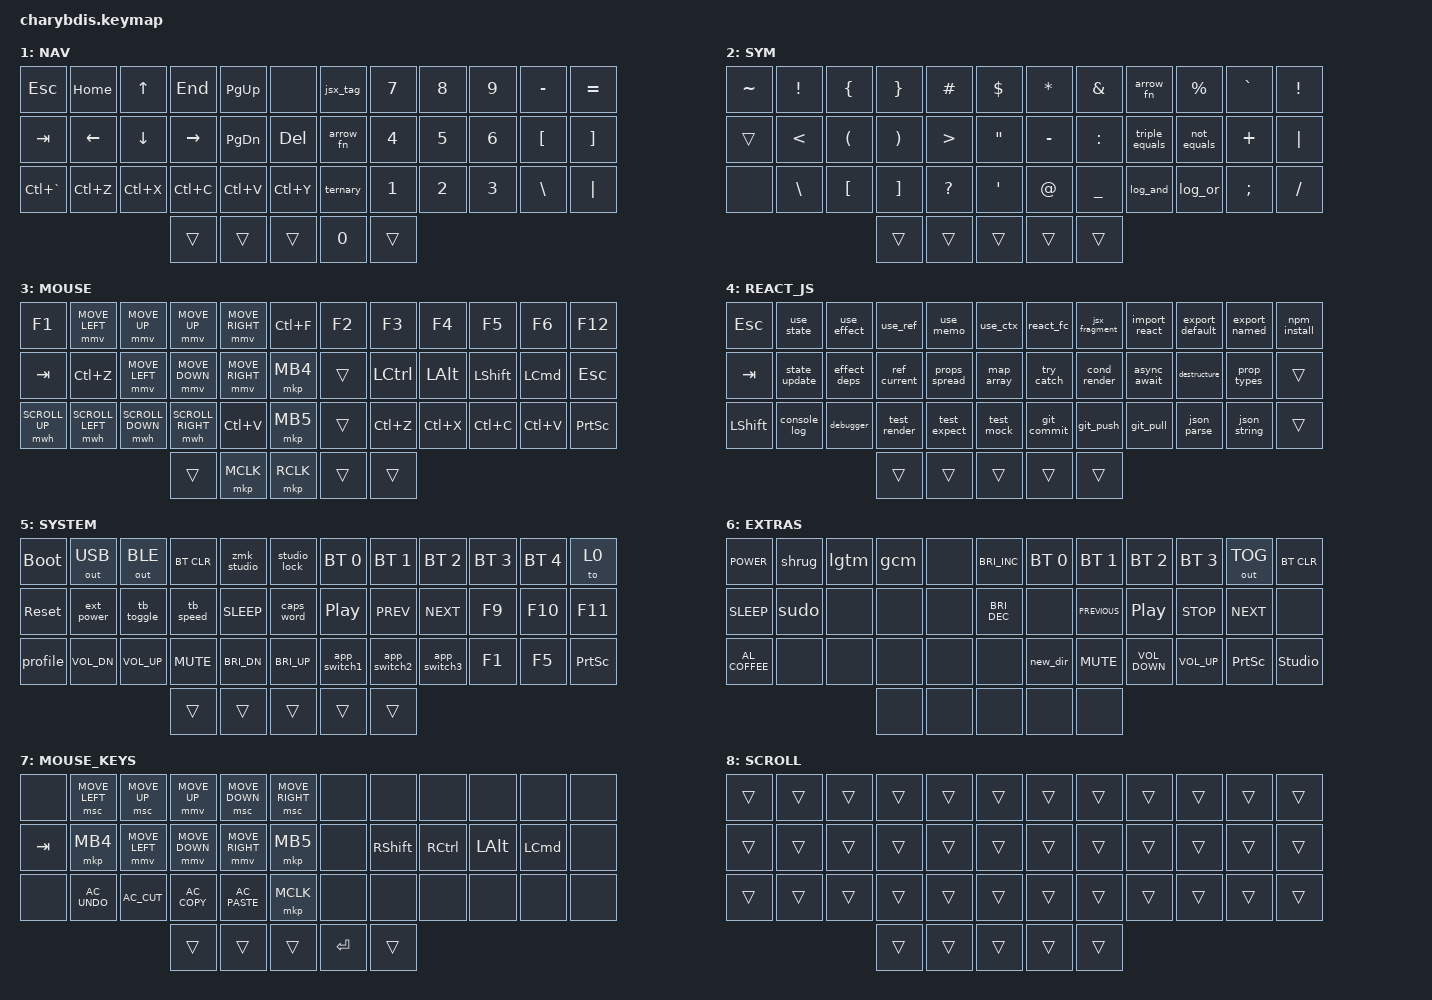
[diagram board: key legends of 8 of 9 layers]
#include <behaviors/mouse_keys.dtsi>
#include <behaviors.dtsi>
#include <dt-bindings/zmk/bt.h>
#include <dt-bindings/zmk/keys.h>
#include <dt-bindings/zmk/mouse.h>
#include <dt-bindings/zmk/outputs.h>

#define U_TAPPING_TERM 200

/ {
    chosen { zmk,matrix_transform = &default_transform; };
};

/ {
    combos {
        compatible = "zmk,combos";

        // Caps Word combo
        CapsWord {
            bindings = <&caps_word>;
            key-positions = <17 18>;
            layers = <0>;
        };

        // Mouse button combos
        MiddleClick {
            bindings = <&mkp MCLK>;
            key-positions = <28 37>;
        };

        RightClick {
            bindings = <&mkp RCLK>;
            key-positions = <16 37>;
        };

        // React/JS layer combo (A+O)
        ReactJSLayer {
            bindings = <&os_react 4>;
            key-positions = <12 22>; // A and O keys
            layers = <0>;
            timeout-ms = <75>; // Strict timing for intentional activation
        };

        // Inner thumb escape combo
        InnerThumbEsc {
            bindings = <&kp ESC>;
            key-positions = <38 39>; // Space and Return keys
            timeout-ms = <150>;
            layers = <0>;
        };

        // Mouse acceleration toggle combo
        MouseAccelToggle {
            bindings = <&mouse_accel_toggle>;
            key-positions = <27 32>; // C and comma keys (center of bottom row)
            timeout-ms = <100>;
            layers = <0 3>; // Available on base layer and mouse layer
        };
    };

    behaviors {
        trackball_listener {
            compatible = "zmk,input-behavior-listener";
            device = <&trackball>;
            layers = <0 1 2>;  // Active on your main layers
            evt-type = <INPUT_EV_REL>;
            x-input-code = <INPUT_REL_X>;
            y-input-code = <INPUT_REL_Y>;
            scale-multiplier = <4>;
            scale-divisor = <5>;
        };
    
        /* Scroll mode configuration */
        trackball_scroll_listener {
            compatible = "zmk,input-behavior-listener";
            device = <&trackball>;
            layers = <5>;  // Using layer 5 for scroll mode
            evt-type = <INPUT_EV_REL>;
            x-input-code = <INPUT_REL_MISC>;  // Horizontal scroll
            y-input-code = <INPUT_REL_WHEEL>; // Vertical scroll
            y-invert;  // Makes scrolling direction feel more natural
            bindings = <&ib_wheel_scaler 1 10>;  // Adjusted for smoother scrolling
        };
    
        /* Scroll wheel scaling behavior */
        ib_wheel_scaler: ib_wheel_scaler {
            compatible = "zmk,input-behavior-scaler";
            #binding-cells = <2>;
            evt-type = <INPUT_EV_REL>;
            input-code = <INPUT_REL_WHEEL>;
        };

        u_mt: u_mt {
            compatible = "zmk,behavior-hold-tap";
            label = "u_mt";
            #binding-cells = <2>;
            tapping_term_ms = <U_TAPPING_TERM>;
            flavor = "tap-preferred";
            bindings = <&kp>, <&kp>;
        };

        u_lt: u_lt {
            compatible = "zmk,behavior-hold-tap";
            label = "u_lt";
            #binding-cells = <2>;
            tapping_term_ms = <U_TAPPING_TERM>;
            flavor = "tap-preferred";
            bindings = <&mo>, <&kp>;
        };

        hm: homerow_mod {
            compatible = "zmk,behavior-hold-tap";
            #binding-cells = <2>;
            flavor = "tap-preferred";
            tapping-term-ms = <175>; // triggers the hold behavior when the tapping-term-ms has expired
            quick-tap-ms = <150>; // If you press a tapped hold-tap again within quick-tap-ms milliseconds of the first press, it will always trigger the tap behavior.
            require-prior-idle-ms = <185>; // like quick-tap-ms however it will apply for any non-modifier key pressed before it
            bindings = <&kp>, <&kp>;  // hold, tap
        };

        hm_right: homerow_mod_right {
            compatible = "zmk,behavior-hold-tap";
            #binding-cells = <2>;
            flavor = "tap-preferred";
            tapping-term-ms = <130>;
            // quick-tap-ms = <200>;
            // require-prior-idle-ms = <150>;
            bindings = <&kp>, <&kp>;
            hold-trigger-key-positions = <0 1 2 3 4 5 12 13 14 15 16 17 24 25 26 27 28 29 36 37 38>;
        };

        hm_left: homerow_mod_left {
            compatible = "zmk,behavior-hold-tap";
            #binding-cells = <2>;
            flavor = "tap-preferred";
            tapping-term-ms = <130>;
            // quick-tap-ms = <200>;
            // require-prior-idle-ms = <150>;
            bindings = <&kp>, <&kp>;
            hold-trigger-key-positions = <6 7 8 9 10 11 18 19 20 21 22 23 30 31 32 33 34 35 39 40>;
        };

        td_cursor: td_scroll_or_cursor {
            compatible = "zmk,behavior-tap-dance";
            #binding-cells = <0>;
            bindings = <&lt 9 ESC>, <&mo 8>; // hold, tap, double_tap
        };

        td_space: td_space {
            compatible = "zmk,behavior-tap-dance";
            #binding-cells = <0>;
            tapping-term-ms = <85>;
            bindings = <&kp SPACE>, <&kp SPACE>; // hold, tap, double_tap
        };

        td_bs: td_bs {
            compatible = "zmk,behavior-tap-dance";
            #binding-cells = <0>;
            tapping-term-ms = <85>;
            bindings = <&kp BACKSPACE>, <&kp BACKSPACE>; // hold, tap, double_tap
        };

        httl: ht_two_layers {
            compatible = "zmk,behavior-hold-tap";
            bindings = <&mo>, <&to>;
            #binding-cells = <2>;
            flavor = "balanced";
            tapping-term-ms = <125>;
        };

        td_layers: td_layer_swap {
            compatible = "zmk,behavior-tap-dance";
            #binding-cells = <0>;
            bindings = <&to 0>, <&to 5>, <&to 6>; // tap, double_tap, tripple_tap
        };

        td_clk_scrl: td_click_or_scroll {
            compatible = "zmk,behavior-tap-dance";
            #binding-cells = <0>;
            tapping-term-ms = <250>;
            bindings = <&mkp RCLK>, <&mo 8>;  // tap/hold, double_tap
        };

        Shift_Enter: Shift_Enter {
            compatible = "zmk,behavior-hold-tap";
            label = "SHIFT_ENTER";
            bindings = <&kp>, <&kp>;

            #binding-cells = <2>;
            hold-trigger-key-positions = <40>;
            tapping-term-ms = <100>;
        };

    macros {
        clip_hist: clip_hist { // CLIPBOARD_HISTORY
            compatible = "zmk,behavior-macro";
            #binding-cells = <0>;
            bindings
                = <&macro_press &kp LGUI>
                , <&macro_tap &kp V>
                , <&macro_release &kp LGUI>
                ;
        };

        studio_unlock_macro: studio_unlock {
            compatible = "zmk,behavior-macro";
            #binding-cells = <0>;
            bindings
                = <&macro_tap &kp LC(K) &kp U>
                ;
        };
        
        // JavaScript Operators
        arrow_fn: arrow_fn {
            compatible = "zmk,behavior-macro";
            #binding-cells = <0>;
            bindings = <&macro_tap &kp EQUAL &kp GREATER_THAN &kp SPACE>;
        };

        ternary: ternary {
            compatible = "zmk,behavior-macro";
            #binding-cells = <0>;
            bindings = <&macro_tap &kp QUESTION &kp SPACE &kp COLON &kp SPACE>;
        };

        triple_equals: triple_equals {
            compatible = "zmk,behavior-macro";
            #binding-cells = <0>;
            bindings = <&macro_tap &kp EQUAL &kp EQUAL &kp EQUAL>;
        };

        not_equals: not_equals {
            compatible = "zmk,behavior-macro";
            #binding-cells = <0>;
            bindings = <&macro_tap &kp EXCL &kp EQUAL &kp EQUAL>;
        };

        log_and: log_and {
            compatible = "zmk,behavior-macro";
            #binding-cells = <0>;
            bindings = <&macro_tap &kp AMPS &kp AMPS>;
        };

        log_or: log_or {
            compatible = "zmk,behavior-macro";
            #binding-cells = <0>;
            bindings = <&macro_tap &kp PIPE &kp PIPE>;
        };

        jsx_tag: jsx_tag {
            compatible = "zmk,behavior-macro";
            #binding-cells = <0>;
            bindings = <&macro_tap
                &kp LT
                &kp GREATER_THAN
                &kp LEFT_ARROW
                &kp LEFT_ARROW
                &kp SLASH
                &kp GREATER_THAN>;
        };

        // React Hooks
        use_state: use_state {
            compatible = "zmk,behavior-macro";
            #binding-cells = <0>;
            bindings = <&macro_tap
                &kp C &kp O &kp N &kp S &kp T &kp SPACE &kp LBKT
                &kp S &kp T &kp A &kp T &kp E &kp COMMA &kp SPACE
                &kp S &kp E &kp T &kp S &kp T &kp A &kp T &kp E
                &kp RBKT &kp SPACE &kp EQUAL &kp SPACE
                &kp U &kp S &kp E &kp S &kp T &kp A &kp T &kp E &kp LPAR &kp RPAR &kp SEMI>;
        };

        use_effect: use_effect {
            compatible = "zmk,behavior-macro";
            #binding-cells = <0>;
            bindings = <&macro_tap
                &kp U &kp S &kp E &kp E &kp F &kp F &kp E &kp C &kp T &kp LPAR
                &kp LPAR &kp RPAR &kp SPACE &kp EQUAL &kp GREATER_THAN &kp SPACE
                &kp LBRC &kp ENTER &kp ENTER &kp RBRC &kp COMMA &kp SPACE
                &kp LBKT &kp RBKT &kp RPAR &kp SEMI &kp UP &kp UP>;
        };

        use_ref: use_ref {
            compatible = "zmk,behavior-macro";
            #binding-cells = <0>;
            bindings = <&macro_tap
                &kp C &kp O &kp N &kp S &kp T &kp SPACE
                &kp R &kp E &kp F &kp SPACE &kp EQUAL &kp SPACE
                &kp U &kp S &kp E &kp R &kp E &kp F &kp LPAR &kp N &kp U &kp L &kp L &kp RPAR &kp SEMI>;
        };

        use_memo: use_memo {
            compatible = "zmk,behavior-macro";
            #binding-cells = <0>;
            bindings = <&macro_tap
                &kp C &kp O &kp N &kp S &kp T &kp SPACE
                &kp M &kp E &kp M &kp O &kp I &kp Z &kp E &kp D &kp SPACE &kp EQUAL &kp SPACE
                &kp U &kp S &kp E &kp M &kp E &kp M &kp O &kp LPAR &kp LPAR &kp RPAR &kp SPACE &kp EQUAL &kp GREATER_THAN &kp SPACE
                &kp LBRC &kp ENTER &kp ENTER &kp RBRC &kp COMMA &kp SPACE
                &kp LBKT &kp RBKT &kp RPAR &kp SEMI>;
        };

        use_ctx: use_ctx {
            compatible = "zmk,behavior-macro";
            #binding-cells = <0>;
            bindings = <&macro_tap
                &kp C &kp O &kp N &kp S &kp T &kp SPACE
                &kp V &kp A &kp L &kp U &kp E &kp SPACE &kp EQUAL &kp SPACE
                &kp U &kp S &kp E &kp C &kp O &kp N &kp T &kp E &kp X &kp T &kp LPAR
                &kp C &kp O &kp N &kp T &kp E &kp X &kp T &kp RPAR &kp SEMI>;
        };

        // React Components
        react_fc: react_fc {
            compatible = "zmk,behavior-macro";
            #binding-cells = <0>;
            bindings = <&macro_tap
                &kp C &kp O &kp N &kp S &kp T &kp SPACE
                &kp C &kp O &kp M &kp P &kp O &kp N &kp E &kp N &kp T &kp SPACE &kp EQUAL &kp SPACE
                &kp LPAR &kp LBRC &kp SPACE &kp P &kp R &kp O &kp P &kp S &kp SPACE &kp RBRC &kp RPAR &kp SPACE &kp EQUAL &kp GREATER_THAN &kp SPACE
                &kp LBRC &kp ENTER &kp ENTER &kp SPACE &kp SPACE &kp R &kp E &kp T &kp U &kp R &kp N &kp SPACE
                &kp LPAR &kp ENTER &kp SPACE &kp SPACE &kp SPACE &kp SPACE
                &kp LT &kp GT &kp LT &kp SLASH &kp GT &kp ENTER
                &kp SPACE &kp SPACE &kp RPAR &kp SEMI &kp ENTER
                &kp RBRC &kp SEMI>;
        };

        jsx_fragment: jsx_fragment {
            compatible = "zmk,behavior-macro";
            #binding-cells = <0>;
            bindings = <&macro_tap
                &kp LT &kp GT &kp ENTER
                &kp SPACE &kp SPACE
                &kp LT &kp SLASH &kp GT>;
        };

        // JS Utilities
        console_log: console_log {
            compatible = "zmk,behavior-macro";
            #binding-cells = <0>;
            bindings = <&macro_tap
                &kp C &kp O &kp N &kp S &kp O &kp L &kp E &kp DOT
                &kp L &kp O &kp G &kp LPAR &kp RPAR &kp SEMI>;
        };

        import_react: import_react {
            compatible = "zmk,behavior-macro";
            #binding-cells = <0>;
            bindings = <&macro_tap
                &kp I &kp M &kp P &kp O &kp R &kp T &kp SPACE
                &kp LBRC &kp SPACE &kp U &kp S &kp E &kp S &kp T &kp A &kp T &kp E &kp COMMA &kp SPACE
                &kp U &kp S &kp E &kp E &kp F &kp F &kp E &kp C &kp T &kp SPACE &kp RBRC &kp SPACE
                &kp F &kp R &kp O &kp M &kp SPACE
                &kp SQT &kp R &kp E &kp A &kp C &kp T &kp SQT &kp SEMI>;
        };

        export_default: export_default {
            compatible = "zmk,behavior-macro";
            #binding-cells = <0>;
            bindings = <&macro_tap
                &kp E &kp X &kp P &kp O &kp R &kp T &kp SPACE
                &kp D &kp E &kp F &kp A &kp U &kp L &kp T &kp SPACE>;
        };

        export_named: export_named {
            compatible = "zmk,behavior-macro";
            #binding-cells = <0>;
            bindings = <&macro_tap
                &kp E &kp X &kp P &kp O &kp R &kp T &kp SPACE
                &kp C &kp O &kp N &kp S &kp T &kp SPACE>;
        };

        state_update: state_update {
            compatible = "zmk,behavior-macro";
            #binding-cells = <0>;
            bindings = <&macro_tap
                &kp S &kp E &kp T &kp S &kp T &kp A &kp T &kp E &kp LPAR
                &kp P &kp R &kp E &kp V &kp SPACE &kp EQUAL &kp GREATER_THAN &kp SPACE
                &kp LPAR &kp RPAR &kp RPAR &kp SEMI>;
        };

        effect_deps: effect_deps {
            compatible = "zmk,behavior-macro";
            #binding-cells = <0>;
            bindings = <&macro_tap
                &kp LBKT &kp RBKT>;
        };

        ref_current: ref_current {
            compatible = "zmk,behavior-macro";
            #binding-cells = <0>;
            bindings = <&macro_tap
                &kp R &kp E &kp F &kp DOT &kp C &kp U &kp R &kp R &kp E &kp N &kp T>;
        };

        props_spread: props_spread {
            compatible = "zmk,behavior-macro";
            #binding-cells = <0>;
            bindings = <&macro_tap
                &kp LBRC &kp DOT &kp DOT &kp DOT &kp P &kp R &kp O &kp P &kp S &kp RBRC>;
        };

        try_catch: try_catch {
            compatible = "zmk,behavior-macro";
            #binding-cells = <0>;
            bindings = <&macro_tap
                &kp T &kp R &kp Y &kp SPACE &kp LBRC &kp ENTER
                &kp SPACE &kp SPACE
                &kp ENTER &kp RBRC &kp SPACE &kp C &kp A &kp T &kp C &kp H &kp SPACE
                &kp LPAR &kp E &kp R &kp R &kp O &kp R &kp RPAR &kp SPACE &kp LBRC &kp ENTER
                &kp SPACE &kp SPACE
                &kp ENTER &kp RBRC>;
        };

        async_await: async_await {
            compatible = "zmk,behavior-macro";
            #binding-cells = <0>;
            bindings = <&macro_tap
                &kp A &kp S &kp Y &kp N &kp C &kp SPACE
                &kp LPAR &kp RPAR &kp SPACE &kp EQUAL &kp GREATER_THAN &kp SPACE
                &kp LBRC &kp ENTER
                &kp SPACE &kp SPACE &kp A &kp W &kp A &kp I &kp T &kp SPACE
                &kp ENTER &kp RBRC>;
        };

        cond_render: cond_render {
            compatible = "zmk,behavior-macro";
            #binding-cells = <0>;
            bindings = <&macro_tap
                &kp LBRC &kp SPACE
                &kp RBRC &kp SPACE &kp AMPS &kp AMPS &kp SPACE &kp LPAR &kp RPAR>;
        };

        map_array: map_array {
            compatible = "zmk,behavior-macro";
            #binding-cells = <0>;
            bindings = <&macro_tap
                &kp DOT &kp M &kp A &kp P &kp LPAR &kp LPAR &kp I &kp T &kp E &kp M &kp COMMA &kp SPACE &kp I &kp N &kp D &kp E &kp X &kp RPAR &kp SPACE
                &kp EQUAL &kp GREATER_THAN &kp SPACE &kp LPAR
                &kp ENTER
                &kp SPACE &kp SPACE
                &kp RPAR &kp RPAR>;
        };

        destructure: destructure {
            compatible = "zmk,behavior-macro";
            #binding-cells = <0>;
            bindings = <&macro_tap
                &kp C &kp O &kp N &kp S &kp T &kp SPACE &kp LBRC &kp SPACE &kp RBRC &kp SPACE &kp EQUAL &kp SPACE>;
        };

        prop_types: prop_types {
            compatible = "zmk,behavior-macro";
            #binding-cells = <0>;
            bindings = <&macro_tap
                &kp C &kp O &kp M &kp P &kp O &kp N &kp E &kp N &kp T &kp DOT &kp P &kp R &kp O &kp P &kp T &kp Y &kp P &kp E &kp S &kp SPACE
                &kp EQUAL &kp SPACE &kp LBRC &kp ENTER
                &kp SPACE &kp SPACE
                &kp ENTER &kp RBRC &kp SEMI>;
        };

        test_render: test_render {
            compatible = "zmk,behavior-macro";
            #binding-cells = <0>;
            bindings = <&macro_tap
                &kp R &kp E &kp N &kp D &kp E &kp R &kp LPAR &kp LT &kp C &kp O &kp M &kp P &kp O &kp N &kp E &kp N &kp T &kp SPACE &kp SLASH &kp GT &kp RPAR>;
        };

        test_expect: test_expect {
            compatible = "zmk,behavior-macro";
            #binding-cells = <0>;
            bindings = <&macro_tap
                &kp E &kp X &kp P &kp E &kp C &kp T &kp LPAR &kp RPAR>;
        };

        test_mock: test_mock {
            compatible = "zmk,behavior-macro";
            #binding-cells = <0>;
            bindings = <&macro_tap
                &kp J &kp E &kp S &kp T &kp DOT &kp M &kp O &kp C &kp K &kp LPAR &kp RPAR>;
        };

        npm_install: npm_install {
            compatible = "zmk,behavior-macro";
            #binding-cells = <0>;
            bindings = <&macro_tap
                &kp N &kp P &kp M &kp SPACE &kp I &kp N &kp S &kp T &kp A &kp L &kp L &kp SPACE>;
        };

        git_commit: git_commit {
            compatible = "zmk,behavior-macro";
            #binding-cells = <0>;
            bindings = <&macro_tap
                &kp G &kp I &kp T &kp SPACE &kp C &kp O &kp M &kp M &kp I &kp T &kp SPACE &kp MINUS &kp M &kp SPACE &kp DQT &kp DQT &kp LEFT>;
        };

        git_push: git_push {
            compatible = "zmk,behavior-macro";
            #binding-cells = <0>;
            bindings = <&macro_tap
                &kp G &kp I &kp T &kp SPACE &kp P &kp U &kp S &kp H>;
        };

        git_pull: git_pull {
            compatible = "zmk,behavior-macro";
            #binding-cells = <0>;
            bindings = <&macro_tap
                &kp G &kp I &kp T &kp SPACE &kp P &kp U &kp L &kp L>;
        };

        json_parse: json_parse {
            compatible = "zmk,behavior-macro";
            #binding-cells = <0>;
            bindings = <&macro_tap
                &kp J &kp S &kp O &kp N &kp DOT &kp P &kp A &kp R &kp S &kp E &kp LPAR &kp RPAR>;
        };

        json_string: json_string {
            compatible = "zmk,behavior-macro";
            #binding-cells = <0>;
            bindings = <&macro_tap
                &kp J &kp S &kp O &kp N &kp DOT &kp S &kp T &kp R &kp I &kp N &kp G &kp I &kp F &kp Y &kp LPAR &kp RPAR>;
        };

        debugger: debugger {
            compatible = "zmk,behavior-macro";
            #binding-cells = <0>;
            bindings = <&macro_tap
                &kp D &kp E &kp B &kp U &kp G &kp G &kp E &kp R &kp SEMI>;
        };

        // System utilities for the SYSTEM layer
        app_switch1: app_switch1 {
            compatible = "zmk,behavior-macro";
            #binding-cells = <0>;
            bindings = <&macro_press &kp LCMD &macro_tap &kp N1 &macro_release &kp LCMD>;
        };

        app_switch2: app_switch2 {
            compatible = "zmk,behavior-macro";
            #binding-cells = <0>;
            bindings = <&macro_press &kp LCMD &macro_tap &kp N2 &macro_release &kp LCMD>;
        };

        app_switch3: app_switch3 {
            compatible = "zmk,behavior-macro";
            #binding-cells = <0>;
            bindings = <&macro_press &kp LCMD &macro_tap &kp N3 &macro_release &kp LCMD>;
        };

        zmk_studio: zmk_studio {
            compatible = "zmk,behavior-macro";
            #binding-cells = <0>;
            bindings = <&macro_tap &kp LCMD &kp K &kp S>;
        };

        studio_lock: studio_lock {
            compatible = "zmk,behavior-macro";
            #binding-cells = <0>;
            bindings = <&macro_tap &kp LCMD &kp K &kp L>;
        };

        tb_toggle: tb_toggle {
            compatible = "zmk,behavior-macro";
            #binding-cells = <0>;
            bindings = <&macro_tap &kp LCMD &kp K &kp T>;
        };

        tb_speed: tb_speed {
            compatible = "zmk,behavior-macro";
            #binding-cells = <0>;
            bindings = <&macro_tap &kp LCMD &kp K &kp P>;
        };

        profile: profile {
            compatible = "zmk,behavior-macro";
            #binding-cells = <0>;
            bindings = <&macro_tap &kp LCMD &kp K &kp O>;
        };

        precision: precision {
            compatible = "zmk,behavior-macro";
            #binding-cells = <0>;
            bindings = <&macro_tap &mo 8>;
        };

        acceleration: acceleration {
            compatible = "zmk,behavior-macro";
            #binding-cells = <0>;
            bindings = <&macro_tap &tog 10>;
        };
    };
    };

    keymap {
        compatible = "zmk,keymap";

        BASE {
            bindings = <
    &kp F12          &kp Q           &kp W                          &kp F                              &kp P                  &kp B       &kp J             &kp L                   &kp U                                   &kp Y                                &kp APOS                 &td_layers
    &hm_left LCMD TAB  &lt 2 A       &hm_left LEFT_ALT R            &hm_left LCTRL S                   &hm_left LEFT_SHIFT T  &kp G       &kp M             &hm_right RIGHT_SHIFT N  &hm_right RCTRL E                       &hm_right RIGHT_ALT I                &lt 2 O                  &kp DEL
    &kp C_AC_SEARCH    &kp Z        &hm_left LC(LA(LEFT_SHIFT)) X  &hm_left LA(LC(LG(LEFT_SHIFT))) C  &kp D                  &kp V       &kp K             &kp H                   &hm_right LA(LC(LG(LEFT_SHIFT))) COMMA  &hm_right LC(LA(LEFT_SHIFT)) PERIOD  &td_home                 &clip_hist
                                                                            &td_cursor      &mkp LCLK          &kp SPACE              &lt 3 RETURN        &kp BACKSPACE
            >;
        };

        NAV {
            bindings = <
    &kp ESC      &kp HOME  &kp UP    &kp END   &kp PG_UP  &none       &jsx_tag   &kp N7    &kp N8    &kp N9    &kp MINUS &kp EQUAL
    &kp TAB      &kp LEFT  &kp DOWN  &kp RIGHT &kp PG_DN  &kp DEL     &arrow_fn  &kp N4    &kp N5    &kp N6    &kp LBKT  &kp RBKT
    &kp LC(GRAVE) &kp LC(Z) &kp LC(X) &kp LC(C) &kp LC(V) &kp LC(Y)   &ternary   &kp N1    &kp N2    &kp N3    &kp BSLH  &kp PIPE
                                      &trans    &trans    &trans       &kp N0    &trans
            >;
        };

       SYM {
            bindings = <
    &kp TILDE    &kp EXCL &kp LBRC &kp RBRC &kp HASH &kp DLLR   &kp ASTRK &kp AMPS &arrow_fn &kp PRCNT &kp GRAVE &kp EXCL
    &trans       &kp LT   &kp LPAR &kp RPAR &kp GT   &kp DQT    &kp MINUS &kp COLON &triple_equals &not_equals &kp PLUS  &kp PIPE
    &none        &kp BSLH &kp LBKT &kp RBKT &kp QMARK &kp SQT   &kp AT    &kp UNDER &log_and &log_or &kp SEMI &kp FSLH
                                 &trans   &trans   &trans     &trans   &trans
            >;
        };

       MOUSE {
            bindings = <
    &kp F1        &mmv MOVE_LEFT &mmv MOVE_UP  &mmv MOVE_UP  &mmv MOVE_RIGHT &kp LC(F)       &kp F2       &kp F3      &kp F4      &kp F5      &kp F6      &kp F12
    &kp TAB       &kp LC(Z)     &mmv MOVE_LEFT &mmv MOVE_DOWN &mmv MOVE_RIGHT &mkp MB4        &trans   &kp LCTRL   &kp LALT    &kp LSHFT   &kp LCMD    &kp ESC
    &mwh SCROLL_UP &mwh SCROLL_LEFT &mwh SCROLL_DOWN &mwh SCROLL_RIGHT &kp LC(V) &mkp MB5    &trans &kp LC(Z)   &kp LC(X)   &kp LC(C)   &kp LC(V)   &kp PSCRN
                                          &trans      &mkp MCLK   &mkp RCLK       &trans      &trans
            >;
        };

       REACT_JS {
            bindings = <
    &kp ESC       &use_state      &use_effect    &use_ref       &use_memo       &use_ctx        &react_fc     &jsx_fragment  &import_react  &export_default &export_named   &npm_install
    &kp TAB       &state_update   &effect_deps   &ref_current   &props_spread   &map_array      &try_catch    &cond_render   &async_await    &destructure    &prop_types     &trans
    &kp LSHIFT    &console_log    &debugger      &test_render   &test_expect    &test_mock      &git_commit   &git_push     &git_pull      &json_parse     &json_string    &trans
                                               &trans         &trans          &trans          &trans        &trans
            >;
        };

       SYSTEM {
            bindings = <
    &bootloader  &out OUT_USB  &out OUT_BLE  &bt BT_CLR    &zmk_studio    &studio_lock      &bt BT_SEL 0  &bt BT_SEL 1  &bt BT_SEL 2  &bt BT_SEL 3  &bt BT_SEL 4  &to 0
    &sys_reset   &ext_power    &tb_toggle    &tb_speed     &kp C_SLEEP    &caps_word        &kp C_PP      &kp C_PREV    &kp C_NEXT    &kp F9        &kp F10       &kp F11
    &profile     &kp C_VOL_DN  &kp C_VOL_UP  &kp C_MUTE    &kp C_BRI_DN   &kp C_BRI_UP      &app_switch1  &app_switch2  &app_switch3  &kp F1        &kp F5        &kp PSCRN
                                             &trans        &trans         &trans            &trans        &trans
            >;
        };

       EXTRAS {
            bindings = <
    &kp C_POWER       &shrug  &lgtm     &gcm      &none  &kp C_BRIGHTNESS_INC    &bt BT_SEL 0  &bt BT_SEL 1    &bt BT_SEL 2       &bt BT_SEL 3  &out OUT_TOG     &bt BT_CLR
    &kp C_SLEEP       &sudo   &none     &none     &none  &kp C_BRIGHTNESS_DEC    &none         &kp C_PREVIOUS  &kp C_PLAY_PAUSE   &kp C_STOP    &kp C_NEXT       &none
    &kp C_AL_COFFEE   &none   &none     &none     &none  &none                   &new_dir      &kp K_MUTE      &kp C_VOLUME_DOWN  &kp C_VOLUME_UP   &kp PRINTSCREEN  &studio_unlock
                                    &none     &none  &none                   &none         &none
            >;
        };

       MOUSE_KEYS {
            bindings = <
    &none    &msc MOVE_LEFT  &msc MOVE_UP    &mmv MOVE_UP    &msc MOVE_DOWN   &msc MOVE_RIGHT    &none  &none            &none      &none         &none          &none
    &kp TAB  &mkp MB4        &mmv MOVE_LEFT  &mmv MOVE_DOWN  &mmv MOVE_RIGHT  &mkp MB5           &none  &kp RIGHT_SHIFT  &kp RCTRL  &kp LEFT_ALT  &kp LCMD  &none
    &none    &kp C_AC_UNDO   &kp C_AC_CUT    &kp C_AC_COPY   &kp C_AC_PASTE   &mkp MCLK          &none  &none            &none      &none         &none          &none
                                         &trans          &trans           &trans             &kp RETURN              &trans
            >;
        };

       SCROLL {
            bindings = <
    &trans    &trans    &trans    &trans    &trans    &trans    &trans    &trans    &trans    &trans    &trans    &trans
    &trans    &trans    &trans    &trans    &trans    &trans    &trans    &trans    &trans    &trans    &trans    &trans
    &trans    &trans    &trans    &trans    &trans    &trans    &trans    &trans    &trans    &trans    &trans    &trans
                                  &trans    &trans    &trans    &trans    &trans
            >;
        };
};
